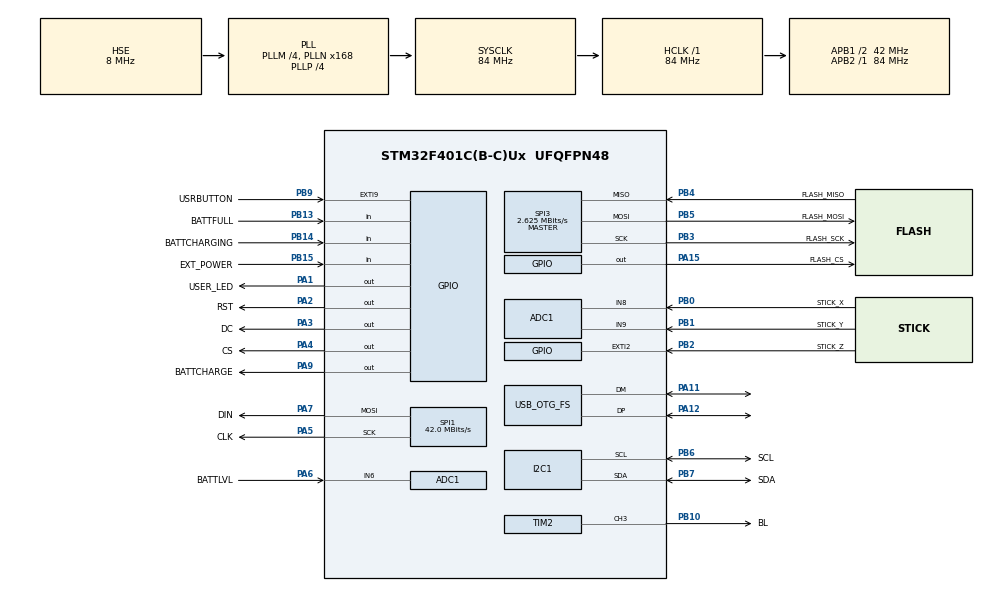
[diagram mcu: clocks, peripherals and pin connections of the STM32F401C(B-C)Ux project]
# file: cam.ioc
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ADC1.Channel-1\#ChannelRegularConversion=ADC_CHANNEL_8
ADC1.Channel-2\#ChannelRegularConversion=ADC_CHANNEL_9
ADC1.Channel-3\#ChannelRegularConversion=ADC_CHANNEL_6
ADC1.DiscontinuousConvMode=ENABLE
ADC1.EOCSelection=ADC_EOC_SEQ_CONV
ADC1.InjNumberOfConversion=0
ADC1.NbrOfConversion=3
ADC1.NbrOfConversionFlag=1
ADC1.NbrOfDiscConversion=1
ADC1.Rank-1\#ChannelRegularConversion=1
ADC1.Rank-2\#ChannelRegularConversion=2
ADC1.Rank-3\#ChannelRegularConversion=3
ADC1.SamplingTime-1\#ChannelRegularConversion=ADC_SAMPLETIME_15CYCLES
ADC1.SamplingTime-2\#ChannelRegularConversion=ADC_SAMPLETIME_15CYCLES
ADC1.SamplingTime-3\#ChannelRegularConversion=ADC_SAMPLETIME_480CYCLES
ADC1.master=1
Dma.I2C1_RX.1.Direction=DMA_PERIPH_TO_MEMORY
Dma.I2C1_RX.1.FIFOMode=DMA_FIFOMODE_DISABLE
Dma.I2C1_RX.1.Instance=DMA1_Stream0
Dma.I2C1_RX.1.MemDataAlignment=DMA_MDATAALIGN_BYTE
Dma.I2C1_RX.1.MemInc=DMA_MINC_ENABLE
Dma.I2C1_RX.1.Mode=DMA_NORMAL
Dma.I2C1_RX.1.PeriphDataAlignment=DMA_PDATAALIGN_BYTE
Dma.I2C1_RX.1.PeriphInc=DMA_PINC_DISABLE
Dma.I2C1_RX.1.Priority=DMA_PRIORITY_LOW
Dma.Request0=SPI1_TX
Dma.Request1=I2C1_RX
Dma.SPI1_TX.0.Direction=DMA_MEMORY_TO_PERIPH
Dma.SPI1_TX.0.FIFOMode=DMA_FIFOMODE_DISABLE
Dma.SPI1_TX.0.Instance=DMA2_Stream3
Dma.SPI1_TX.0.MemDataAlignment=DMA_MDATAALIGN_BYTE
Dma.SPI1_TX.0.MemInc=DMA_MINC_ENABLE
Dma.SPI1_TX.0.Mode=DMA_NORMAL
Dma.SPI1_TX.0.PeriphDataAlignment=DMA_PDATAALIGN_BYTE
Dma.SPI1_TX.0.PeriphInc=DMA_PINC_DISABLE
Dma.SPI1_TX.0.Priority=DMA_PRIORITY_LOW
FATFS._MAX_SS=4096
FATFS._USE_LFN=1
I2C1.I2C_Mode=I2C_Fast
Mcu.Family=STM32F4
Mcu.Name=STM32F401C(B-C)Ux
Mcu.Package=UFQFPN48
NVIC.DMA1_Stream0_IRQn=true\:0\:0\:false\:false\:true\:false\:true\:true
NVIC.DMA2_Stream3_IRQn=true\:0\:0\:false\:false\:true\:false\:true\:true
NVIC.EXTI2_IRQn=true\:0\:0\:false\:false\:true\:true\:true\:true
NVIC.OTG_FS_IRQn=true\:0\:0\:false\:false\:true\:false\:true\:true
NVIC.PriorityGroup=NVIC_PRIORITYGROUP_4
NVIC.SPI1_IRQn=true\:0\:0\:false\:false\:true\:true\:true\:true
PA1.GPIO_Label=USER_LED
PA1.Signal=GPIO_Output
PA11.Mode=Device_Only
PA11.Signal=USB_OTG_FS_DM
PA12.Mode=Device_Only
PA12.Signal=USB_OTG_FS_DP
PA13.Mode=Serial_Wire
PA13.Signal=SYS_JTMS-SWDIO
PA14.Mode=Serial_Wire
PA14.Signal=SYS_JTCK-SWCLK
PA15.GPIO_Label=FLASH_CS
PA15.GPIO_PuPd=GPIO_NOPULL
PA15.GPIO_Speed=GPIO_SPEED_FREQ_VERY_HIGH
PA15.PinState=GPIO_PIN_SET
PA15.Signal=GPIO_Output
PA2.GPIO_Label=RST
PA2.Signal=GPIO_Output
PA3.GPIO_Label=DC
PA3.Signal=GPIO_Output
PA4.GPIO_Label=CS
PA4.Signal=GPIO_Output
PA5.GPIO_Label=CLK
PA5.Mode=TX_Only_Simplex_Unidirect_Master
PA5.Signal=SPI1_SCK
PA6.GPIO_Label=BATTLVL
PA6.Signal=ADCx_IN6
PA7.GPIO_Label=DIN
PA7.Mode=TX_Only_Simplex_Unidirect_Master
PA7.Signal=SPI1_MOSI
PA9.GPIO_Label=BATTCHARGE
PA9.GPIO_ModeDefaultOutputPP=GPIO_MODE_OUTPUT_OD
PA9.GPIO_PuPd=GPIO_NOPULL
PA9.GPIO_Speed=GPIO_SPEED_FREQ_LOW
PA9.PinState=GPIO_PIN_SET
PA9.Signal=GPIO_Output
PB0.GPIO_Label=STICK_X
PB0.Signal=ADCx_IN8
PB1.GPIO_Label=STICK_Y
PB1.Signal=ADCx_IN9
PB10.GPIO_Label=BL
PB10.Signal=S_TIM2_CH3
PB13.GPIO_Label=BATTFULL
PB13.GPIO_PuPd=GPIO_PULLUP
PB13.Signal=GPIO_Input
PB14.GPIO_Label=BATTCHARGING
PB14.GPIO_PuPd=GPIO_PULLUP
PB14.Signal=GPIO_Input
PB15.GPIO_Label=EXT_POWER
PB15.GPIO_PuPd=GPIO_PULLUP
PB15.Signal=GPIO_Input
PB2.GPIO_Label=STICK_Z
PB2.GPIO_ModeDefaultEXTI=GPIO_MODE_IT_FALLING
PB2.GPIO_PuPd=GPIO_NOPULL
PB2.Signal=GPXTI2
PB3.GPIO_Label=FLASH_SCK
PB3.Mode=Full_Duplex_Master
PB3.Signal=SPI3_SCK
PB4.GPIO_Label=FLASH_MISO
PB4.Mode=Full_Duplex_Master
PB4.Signal=SPI3_MISO
PB5.GPIO_Label=FLASH_MOSI
PB5.Mode=Full_Duplex_Master
PB5.Signal=SPI3_MOSI
PB6.GPIO_Label=SCL
PB6.Mode=I2C
PB6.Signal=I2C1_SCL
PB7.GPIO_Label=SDA
PB7.Mode=I2C
PB7.Signal=I2C1_SDA
PB9.GPIO_Label=USRBUTTON
PB9.Signal=GPXTI9
PC14-OSC32_IN.Mode=LSE-External-Oscillator
PC14-OSC32_IN.Signal=RCC_OSC32_IN
PC15-OSC32_OUT.Mode=LSE-External-Oscillator
PC15-OSC32_OUT.Signal=RCC_OSC32_OUT
PH0\ -\ OSC_IN.Mode=HSE-External-Oscillator
PH0\ -\ OSC_IN.Signal=RCC_OSC_IN
PH1\ -\ OSC_OUT.Mode=HSE-External-Oscillator
PH1\ -\ OSC_OUT.Signal=RCC_OSC_OUT
ProjectManager.HeapSize=0x400
ProjectManager.StackSize=0x400
ProjectManager.TargetToolchain=CMake
RCC.48MHZClocksFreq_Value=48000000
RCC.AHBFreq_Value=84000000
RCC.APB1CLKDivider=RCC_HCLK_DIV2
RCC.APB1Freq_Value=42000000
RCC.APB1TimFreq_Value=84000000
RCC.APB2Freq_Value=84000000
RCC.APB2TimFreq_Value=84000000
RCC.CortexFreq_Value=84000000
RCC.HCLKFreq_Value=84000000
RCC.HSE_VALUE=8000000
RCC.HSI_VALUE=16000000
RCC.PLLM=4
RCC.PLLN=168
RCC.PLLP=RCC_PLLP_DIV4
RCC.PLLQ=7
RCC.SYSCLKFreq_VALUE=84000000
RCC.SYSCLKSource=RCC_SYSCLKSOURCE_PLLCLK
RCC.VCOOutputFreq_Value=336000000
SH.ADCx_IN6.0=ADC1_IN6,IN6
SH.ADCx_IN8.0=ADC1_IN8,IN8
SH.ADCx_IN9.0=ADC1_IN9,IN9
SH.S_TIM2_CH3.0=TIM2_CH3,PWM Generation3 CH3
SPI1.BaudRatePrescaler=SPI_BAUDRATEPRESCALER_2
SPI1.CalculateBaudRate=42.0 MBits/s
SPI1.Direction=SPI_DIRECTION_2LINES
SPI1.Mode=SPI_MODE_MASTER
SPI1.VirtualType=VM_MASTER
SPI3.BaudRatePrescaler=SPI_BAUDRATEPRESCALER_16
SPI3.CalculateBaudRate=2.625 MBits/s
SPI3.Direction=SPI_DIRECTION_2LINES
SPI3.Mode=SPI_MODE_MASTER
SPI3.VirtualType=VM_MASTER
STMicroelectronics.X-CUBE-TOUCHGFX.4.27.0.ApplicationCcGraphicsJjApplication=TouchGFXOoGenerator
STMicroelectronics.X-CUBE-TOUCHGFX.4.27.0.tgfx_block_size=12800
STMicroelectronics.X-CUBE-TOUCHGFX.4.27.0.tgfx_buffering_strategy=Partial
STMicroelectronics.X-CUBE-TOUCHGFX.4.27.0.tgfx_custom_height=240
STMicroelectronics.X-CUBE-TOUCHGFX.4.27.0.tgfx_custom_width=320
STMicroelectronics.X-CUBE-TOUCHGFX.4.27.0.tgfx_number_of_blocks=2
STMicroelectronics.X-CUBE-TOUCHGFX.4.27.0_IsPackSelfContextualization=true
TIM2.AutoReloadPreload=TIM_AUTORELOAD_PRELOAD_ENABLE
TIM2.Channel-PWM\ Generation3\ CH3=TIM_CHANNEL_3
TIM2.Period=1000-1
TIM2.Prescaler=300-1
USB_DEVICE.CLASS_NAME_FS=MSC
USB_DEVICE.VirtualMode=Msc
USB_DEVICE.VirtualModeFS=Msc_FS
USB_OTG_FS.VirtualMode=Device_Only
VP_CRC_VS_CRC.Mode=CRC_Activate
VP_FATFS_VS_Generic.Mode=User_defined
VP_STMicroelectronics.X-CUBE-TOUCHGFX_VS_GraphicsJjApplication_4.27.0.Mode=GraphicsJjApplication
VP_USB_DEVICE_VS_USB_DEVICE_MSC_FS.Mode=MSC_FS
board=custom

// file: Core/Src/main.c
/* USER CODE BEGIN Header */
/**
  ******************************************************************************
  * @file           : main.c
  * @brief          : Main program body
  ******************************************************************************
  * @attention
  *
  * Copyright (c) 2026 STMicroelectronics.
  * All rights reserved.
  *
  * This software is licensed under terms that can be found in the LICENSE file
  * in the root directory of this software component.
  * If no LICENSE file comes with this software, it is provided AS-IS.
  *
  ******************************************************************************
  */
/* USER CODE END Header */
#include "main.h"
#include "fatfs.h"

/* USER CODE BEGIN Includes */
#include "application.h"
/* USER CODE END Includes */

ADC_HandleTypeDef hadc1;

I2C_HandleTypeDef hi2c1;
DMA_HandleTypeDef hdma_i2c1_rx;

SPI_HandleTypeDef hspi1;
SPI_HandleTypeDef hspi3;
DMA_HandleTypeDef hdma_spi1_tx;

TIM_HandleTypeDef htim2;

void SystemClock_Config(void);
static void MX_GPIO_Init(void);
static void MX_DMA_Init(void);
static void MX_SPI1_Init(void);
static void MX_ADC1_Init(void);
static void MX_TIM2_Init(void);
static void MX_I2C1_Init(void);
static void MX_SPI3_Init(void);

int main(void)
{

  /* MCU Configuration--------------------------------------------------------*/

  /* Reset of all peripherals, Initializes the Flash interface and the Systick. */
  HAL_Init();

  /* Configure the system clock */
  SystemClock_Config();

  /* Initialize all configured peripherals */
  MX_GPIO_Init();
  MX_DMA_Init();
  MX_SPI1_Init();
  MX_ADC1_Init();
  MX_TIM2_Init();
  MX_I2C1_Init();
  MX_SPI3_Init();
  MX_FATFS_Init();
  /* USER CODE BEGIN 2 */
  application_main();
  /* USER CODE END 2 */

  /* Infinite loop */
  while (1)
  {

  }
}

void SystemClock_Config(void)
{
  RCC_OscInitTypeDef RCC_OscInitStruct = {0};
  RCC_ClkInitTypeDef RCC_ClkInitStruct = {0};

  /** Configure the main internal regulator output voltage
  */
  __HAL_RCC_PWR_CLK_ENABLE();
  __HAL_PWR_VOLTAGESCALING_CONFIG(PWR_REGULATOR_VOLTAGE_SCALE2);

  /** Initializes the RCC Oscillators according to the specified parameters
  * in the RCC_OscInitTypeDef structure.
  */
  RCC_OscInitStruct.OscillatorType = RCC_OSCILLATORTYPE_HSE;
  RCC_OscInitStruct.HSEState = RCC_HSE_ON;
  RCC_OscInitStruct.PLL.PLLState = RCC_PLL_ON;
  RCC_OscInitStruct.PLL.PLLSource = RCC_PLLSOURCE_HSE;
  RCC_OscInitStruct.PLL.PLLM = 4;
  RCC_OscInitStruct.PLL.PLLN = 168;
  RCC_OscInitStruct.PLL.PLLP = RCC_PLLP_DIV4;
  RCC_OscInitStruct.PLL.PLLQ = 7;
  if (HAL_RCC_OscConfig(&RCC_OscInitStruct) != HAL_OK)
  {
    Error_Handler();
  }

  /** Initializes the CPU, AHB and APB buses clocks
  */
  RCC_ClkInitStruct.ClockType = RCC_CLOCKTYPE_HCLK|RCC_CLOCKTYPE_SYSCLK
                              |RCC_CLOCKTYPE_PCLK1|RCC_CLOCKTYPE_PCLK2;
  RCC_ClkInitStruct.SYSCLKSource = RCC_SYSCLKSOURCE_PLLCLK;
  RCC_ClkInitStruct.AHBCLKDivider = RCC_SYSCLK_DIV1;
  RCC_ClkInitStruct.APB1CLKDivider = RCC_HCLK_DIV2;
  RCC_ClkInitStruct.APB2CLKDivider = RCC_HCLK_DIV1;

  if (HAL_RCC_ClockConfig(&RCC_ClkInitStruct, FLASH_LATENCY_2) != HAL_OK)
  {
    Error_Handler();
  }
}

static void MX_ADC1_Init(void)
{

  ADC_ChannelConfTypeDef sConfig = {0};

  /** Configure the global features of the ADC (Clock, Resolution, Data Alignment and number of conversion)
  */
  hadc1.Instance = ADC1;
  hadc1.Init.ClockPrescaler = ADC_CLOCK_SYNC_PCLK_DIV4;
  hadc1.Init.Resolution = ADC_RESOLUTION_12B;
  hadc1.Init.ScanConvMode = ENABLE;
  hadc1.Init.ContinuousConvMode = DISABLE;
  hadc1.Init.DiscontinuousConvMode = ENABLE;
  hadc1.Init.NbrOfDiscConversion = 1;
  hadc1.Init.ExternalTrigConvEdge = ADC_EXTERNALTRIGCONVEDGE_NONE;
  hadc1.Init.ExternalTrigConv = ADC_SOFTWARE_START;
  hadc1.Init.DataAlign = ADC_DATAALIGN_RIGHT;
  hadc1.Init.NbrOfConversion = 3;
  hadc1.Init.DMAContinuousRequests = DISABLE;
  hadc1.Init.EOCSelection = ADC_EOC_SEQ_CONV;
  if (HAL_ADC_Init(&hadc1) != HAL_OK)
  {
    Error_Handler();
  }

  /** Configure for the selected ADC regular channel its corresponding rank in the sequencer and its sample time.
  */
  sConfig.Channel = ADC_CHANNEL_8;
  sConfig.Rank = 1;
  sConfig.SamplingTime = ADC_SAMPLETIME_15CYCLES;
  if (HAL_ADC_ConfigChannel(&hadc1, &sConfig) != HAL_OK)
  {
    Error_Handler();
  }

  /** Configure for the selected ADC regular channel its corresponding rank in the sequencer and its sample time.
  */
  sConfig.Channel = ADC_CHANNEL_9;
  sConfig.Rank = 2;
  if (HAL_ADC_ConfigChannel(&hadc1, &sConfig) != HAL_OK)
  {
    Error_Handler();
  }

  /** Configure for the selected ADC regular channel its corresponding rank in the sequencer and its sample time.
  */
  sConfig.Channel = ADC_CHANNEL_6;
  sConfig.Rank = 3;
  sConfig.SamplingTime = ADC_SAMPLETIME_480CYCLES;
  if (HAL_ADC_ConfigChannel(&hadc1, &sConfig) != HAL_OK)
  {
    Error_Handler();
  }

}

static void MX_I2C1_Init(void)
{

  hi2c1.Instance = I2C1;
  hi2c1.Init.ClockSpeed = 400000;
  hi2c1.Init.DutyCycle = I2C_DUTYCYCLE_2;
  hi2c1.Init.OwnAddress1 = 0;
  hi2c1.Init.AddressingMode = I2C_ADDRESSINGMODE_7BIT;
  hi2c1.Init.DualAddressMode = I2C_DUALADDRESS_DISABLE;
  hi2c1.Init.OwnAddress2 = 0;
  hi2c1.Init.GeneralCallMode = I2C_GENERALCALL_DISABLE;
  hi2c1.Init.NoStretchMode = I2C_NOSTRETCH_DISABLE;
  if (HAL_I2C_Init(&hi2c1) != HAL_OK)
  {
    Error_Handler();
  }

}

static void MX_SPI1_Init(void)
{

  /* SPI1 parameter configuration*/
  hspi1.Instance = SPI1;
  hspi1.Init.Mode = SPI_MODE_MASTER;
  hspi1.Init.Direction = SPI_DIRECTION_2LINES;
  hspi1.Init.DataSize = SPI_DATASIZE_8BIT;
  hspi1.Init.CLKPolarity = SPI_POLARITY_LOW;
  hspi1.Init.CLKPhase = SPI_PHASE_1EDGE;
  hspi1.Init.NSS = SPI_NSS_SOFT;
  hspi1.Init.BaudRatePrescaler = SPI_BAUDRATEPRESCALER_2;
  hspi1.Init.FirstBit = SPI_FIRSTBIT_MSB;
  hspi1.Init.TIMode = SPI_TIMODE_DISABLE;
  hspi1.Init.CRCCalculation = SPI_CRCCALCULATION_DISABLE;
  hspi1.Init.CRCPolynomial = 10;
  if (HAL_SPI_Init(&hspi1) != HAL_OK)
  {
    Error_Handler();
  }

}

static void MX_SPI3_Init(void)
{

  /* SPI3 parameter configuration*/
  hspi3.Instance = SPI3;
  hspi3.Init.Mode = SPI_MODE_MASTER;
  hspi3.Init.Direction = SPI_DIRECTION_2LINES;
  hspi3.Init.DataSize = SPI_DATASIZE_8BIT;
  hspi3.Init.CLKPolarity = SPI_POLARITY_LOW;
  hspi3.Init.CLKPhase = SPI_PHASE_1EDGE;
  hspi3.Init.NSS = SPI_NSS_SOFT;
  hspi3.Init.BaudRatePrescaler = SPI_BAUDRATEPRESCALER_16;
  hspi3.Init.FirstBit = SPI_FIRSTBIT_MSB;
  hspi3.Init.TIMode = SPI_TIMODE_DISABLE;
  hspi3.Init.CRCCalculation = SPI_CRCCALCULATION_DISABLE;
  hspi3.Init.CRCPolynomial = 10;
  if (HAL_SPI_Init(&hspi3) != HAL_OK)
  {
    Error_Handler();
  }

}

static void MX_TIM2_Init(void)
{

  TIM_MasterConfigTypeDef sMasterConfig = {0};
  TIM_OC_InitTypeDef sConfigOC = {0};

  htim2.Instance = TIM2;
  htim2.Init.Prescaler = 300-1;
  htim2.Init.CounterMode = TIM_COUNTERMODE_UP;
  htim2.Init.Period = 1000-1;
  htim2.Init.ClockDivision = TIM_CLOCKDIVISION_DIV1;
  htim2.Init.AutoReloadPreload = TIM_AUTORELOAD_PRELOAD_ENABLE;
  if (HAL_TIM_PWM_Init(&htim2) != HAL_OK)
  {
    Error_Handler();
  }
  sMasterConfig.MasterOutputTrigger = TIM_TRGO_RESET;
  sMasterConfig.MasterSlaveMode = TIM_MASTERSLAVEMODE_DISABLE;
  if (HAL_TIMEx_MasterConfigSynchronization(&htim2, &sMasterConfig) != HAL_OK)
  {
    Error_Handler();
  }
  sConfigOC.OCMode = TIM_OCMODE_PWM1;
  sConfigOC.Pulse = 0;
  sConfigOC.OCPolarity = TIM_OCPOLARITY_HIGH;
  sConfigOC.OCFastMode = TIM_OCFAST_DISABLE;
  if (HAL_TIM_PWM_ConfigChannel(&htim2, &sConfigOC, TIM_CHANNEL_3) != HAL_OK)
  {
    Error_Handler();
  }
  HAL_TIM_MspPostInit(&htim2);

}

static void MX_DMA_Init(void)
{

  /* DMA controller clock enable */
  __HAL_RCC_DMA2_CLK_ENABLE();
  __HAL_RCC_DMA1_CLK_ENABLE();

  /* DMA interrupt init */
  /* DMA1_Stream0_IRQn interrupt configuration */
  HAL_NVIC_SetPriority(DMA1_Stream0_IRQn, 0, 0);
  HAL_NVIC_EnableIRQ(DMA1_Stream0_IRQn);
  /* DMA2_Stream3_IRQn interrupt configuration */
  HAL_NVIC_SetPriority(DMA2_Stream3_IRQn, 0, 0);
  HAL_NVIC_EnableIRQ(DMA2_Stream3_IRQn);

}

static void MX_GPIO_Init(void)
{
  GPIO_InitTypeDef GPIO_InitStruct = {0};

  /* GPIO Ports Clock Enable */
  __HAL_RCC_GPIOC_CLK_ENABLE();
  __HAL_RCC_GPIOH_CLK_ENABLE();
  __HAL_RCC_GPIOA_CLK_ENABLE();
  __HAL_RCC_GPIOB_CLK_ENABLE();

  /*Configure GPIO pin Output Level */
  HAL_GPIO_WritePin(GPIOA, USER_LED_Pin|RST_Pin|DC_Pin|CS_Pin, GPIO_PIN_RESET);

  /*Configure GPIO pin Output Level */
  HAL_GPIO_WritePin(GPIOA, BATTCHARGE_Pin|FLASH_CS_Pin, GPIO_PIN_SET);

  /*Configure GPIO pins : USER_LED_Pin RST_Pin DC_Pin CS_Pin */
  GPIO_InitStruct.Pin = USER_LED_Pin|RST_Pin|DC_Pin|CS_Pin;
  GPIO_InitStruct.Mode = GPIO_MODE_OUTPUT_PP;
  GPIO_InitStruct.Pull = GPIO_NOPULL;
  GPIO_InitStruct.Speed = GPIO_SPEED_FREQ_LOW;
  HAL_GPIO_Init(GPIOA, &GPIO_InitStruct);

  /*Configure GPIO pin : STICK_Z_Pin */
  GPIO_InitStruct.Pin = STICK_Z_Pin;
  GPIO_InitStruct.Mode = GPIO_MODE_IT_FALLING;
  GPIO_InitStruct.Pull = GPIO_NOPULL;
  HAL_GPIO_Init(STICK_Z_GPIO_Port, &GPIO_InitStruct);

  /*Configure GPIO pins : BATTFULL_Pin BATTCHARGING_Pin EXT_POWER_Pin */
  GPIO_InitStruct.Pin = BATTFULL_Pin|BATTCHARGING_Pin|EXT_POWER_Pin;
  GPIO_InitStruct.Mode = GPIO_MODE_INPUT;
  GPIO_InitStruct.Pull = GPIO_PULLUP;
  HAL_GPIO_Init(GPIOB, &GPIO_InitStruct);

  /*Configure GPIO pin : BATTCHARGE_Pin */
  GPIO_InitStruct.Pin = BATTCHARGE_Pin;
  GPIO_InitStruct.Mode = GPIO_MODE_OUTPUT_OD;
  GPIO_InitStruct.Pull = GPIO_NOPULL;
  GPIO_InitStruct.Speed = GPIO_SPEED_FREQ_LOW;
  HAL_GPIO_Init(BATTCHARGE_GPIO_Port, &GPIO_InitStruct);

  /*Configure GPIO pin : FLASH_CS_Pin */
  GPIO_InitStruct.Pin = FLASH_CS_Pin;
  GPIO_InitStruct.Mode = GPIO_MODE_OUTPUT_PP;
  GPIO_InitStruct.Pull = GPIO_NOPULL;
  GPIO_InitStruct.Speed = GPIO_SPEED_FREQ_VERY_HIGH;
  HAL_GPIO_Init(FLASH_CS_GPIO_Port, &GPIO_InitStruct);

  /*Configure GPIO pin : USRBUTTON_Pin */
  GPIO_InitStruct.Pin = USRBUTTON_Pin;
  GPIO_InitStruct.Mode = GPIO_MODE_IT_RISING;
  GPIO_InitStruct.Pull = GPIO_NOPULL;
  HAL_GPIO_Init(USRBUTTON_GPIO_Port, &GPIO_InitStruct);

  /* EXTI interrupt init*/
  HAL_NVIC_SetPriority(EXTI2_IRQn, 0, 0);
  HAL_NVIC_EnableIRQ(EXTI2_IRQn);

}

void Error_Handler(void)
{
  /* USER CODE BEGIN Error_Handler_Debug */
  application_error_handler();
  /* User can add his own implementation to report the HAL error return state */
  __disable_irq();
  while (1)
  {
  }
  /* USER CODE END Error_Handler_Debug */
}
